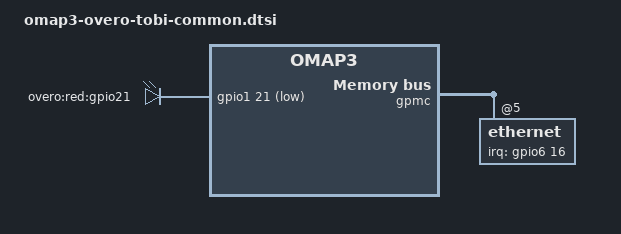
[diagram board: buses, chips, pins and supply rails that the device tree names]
#include "omap3-overo-common-peripherals.dtsi"
#include "omap3-overo-common-dvi.dtsi"
/ {
	leds {
		compatible = "gpio-leds";
		led-heartbeat {
			label = "overo:red:gpio21";
			gpios = <&gpio1 21 GPIO_ACTIVE_LOW>;
			linux,default-trigger = "heartbeat";
		};
	};
};
#include "omap-gpmc-smsc9221.dtsi"
&gpmc {
	ethernet@gpmc {
		reg = <5 0 0xff>;
		interrupt-parent = <&gpio6>;
		interrupts = <16 IRQ_TYPE_LEVEL_LOW>;	 
	};
};
&lis33de {
	status = "disabled";
};
